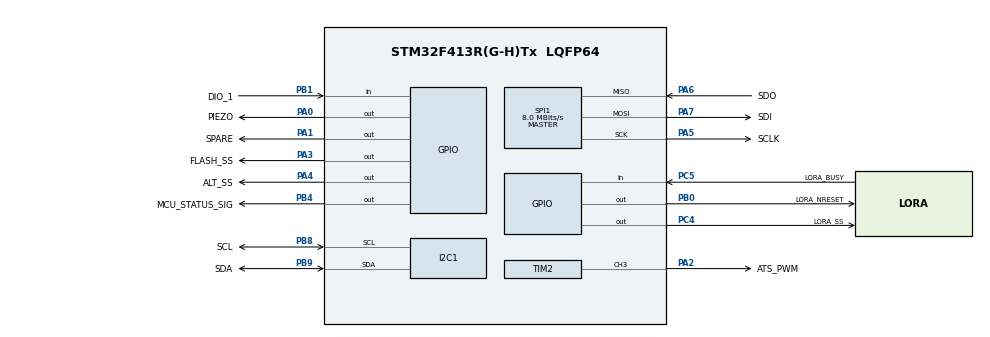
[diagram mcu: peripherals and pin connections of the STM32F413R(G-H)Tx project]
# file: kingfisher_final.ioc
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Mcu.Family=STM32F4
Mcu.Name=STM32F413R(G-H)Tx
Mcu.Package=LQFP64
NVIC.PriorityGroup=NVIC_PRIORITYGROUP_4
PA0.GPIO_Label=PIEZO
PA0.Signal=GPIO_Output
PA1.GPIO_Label=SPARE
PA1.Signal=GPIO_Output
PA2.GPIO_Label=ATS_PWM
PA2.Signal=S_TIM2_CH3
PA3.GPIO_Label=FLASH_SS
PA3.PinState=GPIO_PIN_SET
PA3.Signal=GPIO_Output
PA4.GPIO_Label=ALT_SS
PA4.GPIO_Speed=GPIO_SPEED_FREQ_VERY_HIGH
PA4.PinState=GPIO_PIN_SET
PA4.Signal=GPIO_Output
PA5.GPIO_Label=SCLK
PA5.Mode=Full_Duplex_Master
PA5.Signal=SPI1_SCK
PA6.GPIO_Label=SDO
PA6.Mode=Full_Duplex_Master
PA6.Signal=SPI1_MISO
PA7.GPIO_Label=SDI
PA7.Mode=Full_Duplex_Master
PA7.Signal=SPI1_MOSI
PB0.GPIO_Label=LORA_NRESET
PB0.Signal=GPIO_Output
PB1.GPIO_Label=DIO_1
PB1.Signal=GPIO_Input
PB3.Mode=Trace_Asynchronous_SW
PB3.Signal=SYS_JTDO-SWO
PB4.GPIO_Label=MCU_STATUS_SIG
PB4.Signal=GPIO_Output
PB8.GPIO_Label=SCL
PB8.Mode=I2C
PB8.Signal=I2C1_SCL
PB9.GPIO_Label=SDA
PB9.Mode=I2C
PB9.Signal=I2C1_SDA
PC4.GPIO_Label=LORA_SS
PC4.GPIO_Speed=GPIO_SPEED_FREQ_VERY_HIGH
PC4.PinState=GPIO_PIN_SET
PC4.Signal=GPIO_Output
PC5.GPIO_Label=LORA_BUSY
PC5.Signal=GPIO_Input
ProjectManager.HeapSize=0x200
ProjectManager.StackSize=0x400
ProjectManager.TargetToolchain=STM32CubeIDE
RCC.CortexFreq_Value=16000000
RCC.HSE_VALUE=25000000
RCC.PLLM=25
RCC.PLLN=192
RCC.PLLP=RCC_PLLP_DIV4
RCC.PLLQ=4
RCC.PLLSourceVirtual=RCC_PLLSOURCE_HSE
RCC.USBFreq_Value=48000000
RCC.VCOOutputFreq_Value=192000000
SH.S_TIM2_CH3.0=TIM2_CH3,PWM Generation3 CH3
SPI1.CalculateBaudRate=8.0 MBits/s
SPI1.Direction=SPI_DIRECTION_2LINES
SPI1.Mode=SPI_MODE_MASTER
SPI1.VirtualType=VM_MASTER
SYS.Debug=Trace_Asynchronous_SW
TIM2.Channel-PWM\ Generation3\ CH3=TIM_CHANNEL_3
board=custom

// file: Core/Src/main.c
/* USER CODE BEGIN Header */
/**
  ******************************************************************************
  * @file           : main.c
  * @brief          : Main program body
  ******************************************************************************
  * @attention
  *
  * Copyright (c) 2026 STMicroelectronics.
  * All rights reserved.
  *
  * This software is licensed under terms that can be found in the LICENSE file
  * in the root directory of this software component.
  * If no LICENSE file comes with this software, it is provided AS-IS.
  *
  ******************************************************************************
  */
/* USER CODE END Header */
#include "main.h"

/* USER CODE BEGIN Includes */
#include "ats.h"
#include "ats_config.h"
/* USER CODE END Includes */

I2C_HandleTypeDef hi2c1;

SPI_HandleTypeDef hspi1;

TIM_HandleTypeDef htim2;

void SystemClock_Config(void);
static void MX_GPIO_Init(void);
static void MX_I2C1_Init(void);
static void MX_SPI1_Init(void);
static void MX_TIM2_Init(void);

int main(void)
{

  /* MCU Configuration--------------------------------------------------------*/

  /* Reset of all peripherals, Initializes the Flash interface and the Systick. */
  HAL_Init();

  /* Configure the system clock */
  SystemClock_Config();

  /* Initialize all configured peripherals */
  MX_GPIO_Init();
  MX_I2C1_Init();
  MX_SPI1_Init();
  MX_TIM2_Init();
  /* USER CODE BEGIN 2 */
  ats_init();
  /* USER CODE END 2 */

  /* Infinite loop */
  while (1)
  {

    /* USER CODE BEGIN 3 */
    ats_run_once();
  }
  /* USER CODE END 3 */
}

void SystemClock_Config(void)
{
  RCC_OscInitTypeDef RCC_OscInitStruct = {0};
  RCC_ClkInitTypeDef RCC_ClkInitStruct = {0};

  /** Configure the main internal regulator output voltage
  */
  __HAL_RCC_PWR_CLK_ENABLE();
  __HAL_PWR_VOLTAGESCALING_CONFIG(PWR_REGULATOR_VOLTAGE_SCALE1);

  /** Initializes the RCC Oscillators according to the specified parameters
  * in the RCC_OscInitTypeDef structure.
  */
  RCC_OscInitStruct.OscillatorType = RCC_OSCILLATORTYPE_HSI;
  RCC_OscInitStruct.HSIState = RCC_HSI_ON;
  RCC_OscInitStruct.HSICalibrationValue = RCC_HSICALIBRATION_DEFAULT;
  RCC_OscInitStruct.PLL.PLLState = RCC_PLL_NONE;
  if (HAL_RCC_OscConfig(&RCC_OscInitStruct) != HAL_OK)
  {
    Error_Handler();
  }

  /** Initializes the CPU, AHB and APB buses clocks
  */
  RCC_ClkInitStruct.ClockType = RCC_CLOCKTYPE_HCLK|RCC_CLOCKTYPE_SYSCLK
                              |RCC_CLOCKTYPE_PCLK1|RCC_CLOCKTYPE_PCLK2;
  RCC_ClkInitStruct.SYSCLKSource = RCC_SYSCLKSOURCE_HSI;
  RCC_ClkInitStruct.AHBCLKDivider = RCC_SYSCLK_DIV1;
  RCC_ClkInitStruct.APB1CLKDivider = RCC_HCLK_DIV1;
  RCC_ClkInitStruct.APB2CLKDivider = RCC_HCLK_DIV1;

  if (HAL_RCC_ClockConfig(&RCC_ClkInitStruct, FLASH_LATENCY_0) != HAL_OK)
  {
    Error_Handler();
  }
}

static void MX_I2C1_Init(void)
{

  hi2c1.Instance = I2C1;
  hi2c1.Init.ClockSpeed = 100000;
  hi2c1.Init.DutyCycle = I2C_DUTYCYCLE_2;
  hi2c1.Init.OwnAddress1 = 0;
  hi2c1.Init.AddressingMode = I2C_ADDRESSINGMODE_7BIT;
  hi2c1.Init.DualAddressMode = I2C_DUALADDRESS_DISABLE;
  hi2c1.Init.OwnAddress2 = 0;
  hi2c1.Init.GeneralCallMode = I2C_GENERALCALL_DISABLE;
  hi2c1.Init.NoStretchMode = I2C_NOSTRETCH_DISABLE;
  if (HAL_I2C_Init(&hi2c1) != HAL_OK)
  {
    Error_Handler();
  }

}

static void MX_SPI1_Init(void)
{

  /* SPI1 parameter configuration*/
  hspi1.Instance = SPI1;
  hspi1.Init.Mode = SPI_MODE_MASTER;
  hspi1.Init.Direction = SPI_DIRECTION_2LINES;
  hspi1.Init.DataSize = SPI_DATASIZE_8BIT;
  hspi1.Init.CLKPolarity = SPI_POLARITY_LOW;
  hspi1.Init.CLKPhase = SPI_PHASE_1EDGE;
  hspi1.Init.NSS = SPI_NSS_SOFT;
  hspi1.Init.BaudRatePrescaler = SPI_BAUDRATEPRESCALER_2;
  hspi1.Init.FirstBit = SPI_FIRSTBIT_MSB;
  hspi1.Init.TIMode = SPI_TIMODE_DISABLE;
  hspi1.Init.CRCCalculation = SPI_CRCCALCULATION_DISABLE;
  hspi1.Init.CRCPolynomial = 10;
  if (HAL_SPI_Init(&hspi1) != HAL_OK)
  {
    Error_Handler();
  }

}

static void MX_TIM2_Init(void)
{

  TIM_MasterConfigTypeDef sMasterConfig = {0};
  TIM_OC_InitTypeDef sConfigOC = {0};

  htim2.Instance = TIM2;
  htim2.Init.Prescaler = 0;
  htim2.Init.CounterMode = TIM_COUNTERMODE_UP;
  htim2.Init.Period = 4294967295;
  htim2.Init.ClockDivision = TIM_CLOCKDIVISION_DIV1;
  htim2.Init.AutoReloadPreload = TIM_AUTORELOAD_PRELOAD_DISABLE;
  if (HAL_TIM_PWM_Init(&htim2) != HAL_OK)
  {
    Error_Handler();
  }
  sMasterConfig.MasterOutputTrigger = TIM_TRGO_RESET;
  sMasterConfig.MasterSlaveMode = TIM_MASTERSLAVEMODE_DISABLE;
  if (HAL_TIMEx_MasterConfigSynchronization(&htim2, &sMasterConfig) != HAL_OK)
  {
    Error_Handler();
  }
  sConfigOC.OCMode = TIM_OCMODE_PWM1;
  sConfigOC.Pulse = 0;
  sConfigOC.OCPolarity = TIM_OCPOLARITY_HIGH;
  sConfigOC.OCFastMode = TIM_OCFAST_DISABLE;
  if (HAL_TIM_PWM_ConfigChannel(&htim2, &sConfigOC, TIM_CHANNEL_3) != HAL_OK)
  {
    Error_Handler();
  }
  HAL_TIM_MspPostInit(&htim2);

}

static void MX_GPIO_Init(void)
{
  GPIO_InitTypeDef GPIO_InitStruct = {0};

  /* GPIO Ports Clock Enable */
  __HAL_RCC_GPIOA_CLK_ENABLE();
  __HAL_RCC_GPIOC_CLK_ENABLE();
  __HAL_RCC_GPIOB_CLK_ENABLE();

  /*Configure GPIO pin Output Level */
  HAL_GPIO_WritePin(GPIOA, PIEZO_Pin|SPARE_Pin, GPIO_PIN_RESET);

  /*Configure GPIO pin Output Level */
  HAL_GPIO_WritePin(GPIOA, FLASH_SS_Pin|ALT_SS_Pin, GPIO_PIN_SET);

  /*Configure GPIO pin Output Level */
  HAL_GPIO_WritePin(LORA_SS_GPIO_Port, LORA_SS_Pin, GPIO_PIN_SET);

  /*Configure GPIO pin Output Level */
  HAL_GPIO_WritePin(GPIOB, LORA_NRESET_Pin|MCU_STATUS_SIG_Pin, GPIO_PIN_RESET);

  /*Configure GPIO pins : PIEZO_Pin SPARE_Pin FLASH_SS_Pin */
  GPIO_InitStruct.Pin = PIEZO_Pin|SPARE_Pin|FLASH_SS_Pin;
  GPIO_InitStruct.Mode = GPIO_MODE_OUTPUT_PP;
  GPIO_InitStruct.Pull = GPIO_NOPULL;
  GPIO_InitStruct.Speed = GPIO_SPEED_FREQ_LOW;
  HAL_GPIO_Init(GPIOA, &GPIO_InitStruct);

  /*Configure GPIO pin : ALT_SS_Pin */
  GPIO_InitStruct.Pin = ALT_SS_Pin;
  GPIO_InitStruct.Mode = GPIO_MODE_OUTPUT_PP;
  GPIO_InitStruct.Pull = GPIO_NOPULL;
  GPIO_InitStruct.Speed = GPIO_SPEED_FREQ_VERY_HIGH;
  HAL_GPIO_Init(ALT_SS_GPIO_Port, &GPIO_InitStruct);

  /*Configure GPIO pin : LORA_SS_Pin */
  GPIO_InitStruct.Pin = LORA_SS_Pin;
  GPIO_InitStruct.Mode = GPIO_MODE_OUTPUT_PP;
  GPIO_InitStruct.Pull = GPIO_NOPULL;
  GPIO_InitStruct.Speed = GPIO_SPEED_FREQ_VERY_HIGH;
  HAL_GPIO_Init(LORA_SS_GPIO_Port, &GPIO_InitStruct);

  /*Configure GPIO pin : LORA_BUSY_Pin */
  GPIO_InitStruct.Pin = LORA_BUSY_Pin;
  GPIO_InitStruct.Mode = GPIO_MODE_INPUT;
  GPIO_InitStruct.Pull = GPIO_NOPULL;
  HAL_GPIO_Init(LORA_BUSY_GPIO_Port, &GPIO_InitStruct);

  /*Configure GPIO pins : LORA_NRESET_Pin MCU_STATUS_SIG_Pin */
  GPIO_InitStruct.Pin = LORA_NRESET_Pin|MCU_STATUS_SIG_Pin;
  GPIO_InitStruct.Mode = GPIO_MODE_OUTPUT_PP;
  GPIO_InitStruct.Pull = GPIO_NOPULL;
  GPIO_InitStruct.Speed = GPIO_SPEED_FREQ_LOW;
  HAL_GPIO_Init(GPIOB, &GPIO_InitStruct);

  /*Configure GPIO pin : DIO_1_Pin */
  GPIO_InitStruct.Pin = DIO_1_Pin;
  GPIO_InitStruct.Mode = GPIO_MODE_INPUT;
  GPIO_InitStruct.Pull = GPIO_NOPULL;
  HAL_GPIO_Init(DIO_1_GPIO_Port, &GPIO_InitStruct);

}

void Error_Handler(void)
{
  __disable_irq();
  while (1)
  {
  }
}
